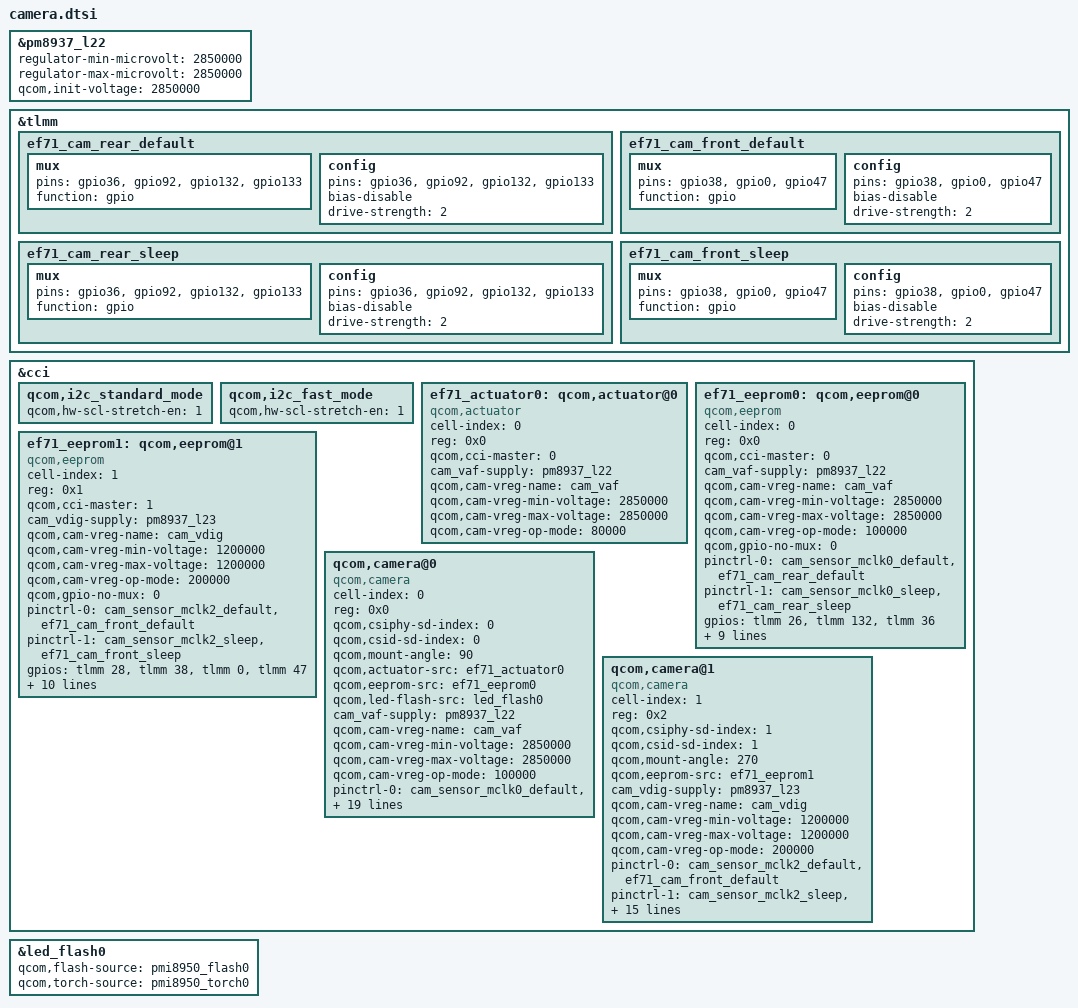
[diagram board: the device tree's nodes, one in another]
// SPDX-License-Identifier: GPL-2.0-only

/*
 * Rear IMX214 (13M, VCM, OTP behind the dw9763) on CCI master 0 and front
 * S5K5E2 (5M, OTP in the sensor) on CCI master 1, both powered through
 * enable GPIOs. Values from the msm-3.18 EF71 TP20 device tree; the
 * enable GPIOs need CONFIG_PANTECH_CAMERA in camera-legacy-m.
 */

/* VREG_L22 feeds the rear AF/AVDD at 2.85 V on the EF71, not 2.8 V */
&pm8937_l22 {
	regulator-min-microvolt = <2850000>;
	regulator-max-microvolt = <2850000>;
	qcom,init-voltage = <2850000>;
};

&tlmm {
	ef71_cam_rear_default: ef71_cam_rear_default {
		/* RESET, 13M_DVDD_EN, 13M_IOVDD_EN, 13M_AVDD_EN */
		mux {
			pins = "gpio36", "gpio92", "gpio132", "gpio133";
			function = "gpio";
		};

		config {
			pins = "gpio36", "gpio92", "gpio132", "gpio133";
			bias-disable;
			drive-strength = <2>;
		};
	};

	ef71_cam_rear_sleep: ef71_cam_rear_sleep {
		mux {
			pins = "gpio36", "gpio92", "gpio132", "gpio133";
			function = "gpio";
		};

		config {
			pins = "gpio36", "gpio92", "gpio132", "gpio133";
			bias-disable;
			drive-strength = <2>;
		};
	};

	ef71_cam_front_default: ef71_cam_front_default {
		/* RESET, 5M_AVDD_EN, 5M_VDDIO_EN */
		mux {
			pins = "gpio38", "gpio0", "gpio47";
			function = "gpio";
		};

		config {
			pins = "gpio38", "gpio0", "gpio47";
			bias-disable;
			drive-strength = <2>;
		};
	};

	ef71_cam_front_sleep: ef71_cam_front_sleep {
		mux {
			pins = "gpio38", "gpio0", "gpio47";
			function = "gpio";
		};

		config {
			pins = "gpio38", "gpio0", "gpio47";
			bias-disable;
			drive-strength = <2>;
		};
	};
};

&cci {
	/*
	 * The S5K5E2 stretches SCL: without clock stretching the CCI master
	 * gives up on its reads (msm-3.18 EF71 enabled it for both modes).
	 */
	qcom,i2c_standard_mode {
		qcom,hw-scl-stretch-en = <1>;
	};

	qcom,i2c_fast_mode {
		qcom,hw-scl-stretch-en = <1>;
	};

	/* The MTP camera modules are not fitted */
	/delete-node/ qcom,actuator@0;
	/delete-node/ qcom,actuator@1;
	/delete-node/ qcom,eeprom@0;
	/delete-node/ qcom,eeprom@1;
	/delete-node/ qcom,camera@0;
	/delete-node/ qcom,camera@1;
	/delete-node/ qcom,camera@2;

	ef71_actuator0: qcom,actuator@0 {
		cell-index = <0>;
		reg = <0x0>;
		compatible = "qcom,actuator";
		qcom,cci-master = <0>;
		cam_vaf-supply = <&pm8937_l22>;
		qcom,cam-vreg-name = "cam_vaf";
		qcom,cam-vreg-min-voltage = <2850000>;
		qcom,cam-vreg-max-voltage = <2850000>;
		qcom,cam-vreg-op-mode = <80000>;
	};

	/* Rear module OTP, probed from userspace */
	ef71_eeprom0: qcom,eeprom@0 {
		cell-index = <0>;
		reg = <0x0>;
		compatible = "qcom,eeprom";
		qcom,cci-master = <0>;
		cam_vaf-supply = <&pm8937_l22>;
		qcom,cam-vreg-name = "cam_vaf";
		qcom,cam-vreg-min-voltage = <2850000>;
		qcom,cam-vreg-max-voltage = <2850000>;
		qcom,cam-vreg-op-mode = <100000>;
		qcom,gpio-no-mux = <0>;
		pinctrl-names = "cam_default", "cam_suspend";
		pinctrl-0 = <&cam_sensor_mclk0_default &ef71_cam_rear_default>;
		pinctrl-1 = <&cam_sensor_mclk0_sleep &ef71_cam_rear_sleep>;
		gpios = <&tlmm 26 0>,
			<&tlmm 132 0>,
			<&tlmm 36 0>;
		qcom,gpio-iovdd-en = <1>;
		qcom,gpio-reset = <2>;
		qcom,gpio-req-tbl-num = <0 1 2>;
		qcom,gpio-req-tbl-flags = <1 0 0>;
		qcom,gpio-req-tbl-label = "CAMIF_MCLK0",
			"CAM_IOVDD0",
			"CAM_RESET0";
		status = "ok";
		clocks = <&gcc MCLK0_CLK_SRC>,
			<&gcc GCC_CAMSS_MCLK0_CLK>;
		clock-names = "cam_src_clk", "cam_clk";
		qcom,clock-rates = <24000000 0>;
	};

	/* Front sensor OTP, probed from userspace */
	ef71_eeprom1: qcom,eeprom@1 {
		cell-index = <1>;
		reg = <0x1>;
		compatible = "qcom,eeprom";
		qcom,cci-master = <1>;
		cam_vdig-supply = <&pm8937_l23>;
		qcom,cam-vreg-name = "cam_vdig";
		qcom,cam-vreg-min-voltage = <1200000>;
		qcom,cam-vreg-max-voltage = <1200000>;
		qcom,cam-vreg-op-mode = <200000>;
		qcom,gpio-no-mux = <0>;
		pinctrl-names = "cam_default", "cam_suspend";
		pinctrl-0 = <&cam_sensor_mclk2_default &ef71_cam_front_default>;
		pinctrl-1 = <&cam_sensor_mclk2_sleep &ef71_cam_front_sleep>;
		gpios = <&tlmm 28 0>,
			<&tlmm 38 0>,
			<&tlmm 0 0>,
			<&tlmm 47 0>;
		qcom,gpio-reset = <1>;
		qcom,gpio-avdd-en = <2>;
		qcom,gpio-vddio-en = <3>;
		qcom,gpio-req-tbl-num = <0 1 2 3>;
		qcom,gpio-req-tbl-flags = <1 0 0 0>;
		qcom,gpio-req-tbl-label = "CAMIF_MCLK2",
			"CAM_RESET1",
			"CAM_AVDD1",
			"CAM_VDDIO1";
		status = "ok";
		clocks = <&gcc MCLK2_CLK_SRC>,
			<&gcc GCC_CAMSS_MCLK2_CLK>;
		clock-names = "cam_src_clk", "cam_clk";
		qcom,clock-rates = <24000000 0>;
	};

	qcom,camera@0 {
		cell-index = <0>;
		compatible = "qcom,camera";
		reg = <0x0>;
		qcom,csiphy-sd-index = <0>;
		qcom,csid-sd-index = <0>;
		qcom,mount-angle = <90>;
		qcom,actuator-src = <&ef71_actuator0>;
		qcom,eeprom-src = <&ef71_eeprom0>;
		qcom,led-flash-src = <&led_flash0>;
		cam_vaf-supply = <&pm8937_l22>;
		qcom,cam-vreg-name = "cam_vaf";
		qcom,cam-vreg-min-voltage = <2850000>;
		qcom,cam-vreg-max-voltage = <2850000>;
		qcom,cam-vreg-op-mode = <100000>;
		pinctrl-names = "cam_default", "cam_suspend";
		pinctrl-0 = <&cam_sensor_mclk0_default &ef71_cam_rear_default>;
		pinctrl-1 = <&cam_sensor_mclk0_sleep &ef71_cam_rear_sleep>;
		gpios = <&tlmm 26 0>,
			<&tlmm 36 0>,	/* CAM0_RST_N */
			<&tlmm 92 0>,	/* 13M_DVDD_EN */
			<&tlmm 132 0>,	/* 13M_IOVDD_EN */
			<&tlmm 133 0>;	/* 13M_AVDD_EN */
		qcom,gpio-reset = <1>;
		qcom,gpio-dvdd-en = <2>;
		qcom,gpio-iovdd-en = <3>;
		qcom,gpio-avdd-en = <4>;
		qcom,gpio-req-tbl-num = <0 1 2 3 4>;
		qcom,gpio-req-tbl-flags = <1 0 0 0 0>;
		qcom,gpio-req-tbl-label = "CAMIF_MCLK0",
			"CAM_RESET0",
			"CAM_DVDD0",
			"CAM_IOVDD0",
			"CAM_AVDD0";
		qcom,sensor-position = <0>;
		qcom,sensor-mode = <0>;
		qcom,cci-master = <0>;
		status = "ok";
		clocks = <&gcc MCLK0_CLK_SRC>,
			<&gcc GCC_CAMSS_MCLK0_CLK>;
		clock-names = "cam_src_clk", "cam_clk";
		qcom,clock-rates = <24000000 0>;
	};

	qcom,camera@1 {
		cell-index = <1>;
		compatible = "qcom,camera";
		reg = <0x2>;
		qcom,csiphy-sd-index = <1>;
		qcom,csid-sd-index = <1>;
		qcom,mount-angle = <270>;
		qcom,eeprom-src = <&ef71_eeprom1>;
		cam_vdig-supply = <&pm8937_l23>;
		qcom,cam-vreg-name = "cam_vdig";
		qcom,cam-vreg-min-voltage = <1200000>;
		qcom,cam-vreg-max-voltage = <1200000>;
		qcom,cam-vreg-op-mode = <200000>;
		pinctrl-names = "cam_default", "cam_suspend";
		pinctrl-0 = <&cam_sensor_mclk2_default &ef71_cam_front_default>;
		pinctrl-1 = <&cam_sensor_mclk2_sleep &ef71_cam_front_sleep>;
		gpios = <&tlmm 28 0>,
			<&tlmm 38 0>,	/* CAM1_RST_N */
			<&tlmm 0 0>,	/* 5M_AVDD_EN */
			<&tlmm 47 0>;	/* 5M_VDDIO_EN */
		qcom,gpio-reset = <1>;
		qcom,gpio-avdd-en = <2>;
		qcom,gpio-vddio-en = <3>;
		qcom,gpio-req-tbl-num = <0 1 2 3>;
		qcom,gpio-req-tbl-flags = <1 0 0 0>;
		qcom,gpio-req-tbl-label = "CAMIF_MCLK2",
			"CAM_RESET1",
			"CAM_AVDD1",
			"CAM_VDDIO1";
		qcom,sensor-position = <1>;
		qcom,sensor-mode = <1>;
		qcom,cci-master = <1>;
		status = "ok";
		clocks = <&gcc MCLK2_CLK_SRC>,
			<&gcc GCC_CAMSS_MCLK2_CLK>;
		clock-names = "cam_src_clk", "cam_clk";
		qcom,clock-rates = <24000000 0>;
	};
};

/* Only flash_0 and torch_0 are wired */
&led_flash0 {
	qcom,flash-source = <&pmi8950_flash0>;
	qcom,torch-source = <&pmi8950_torch0>;
};
